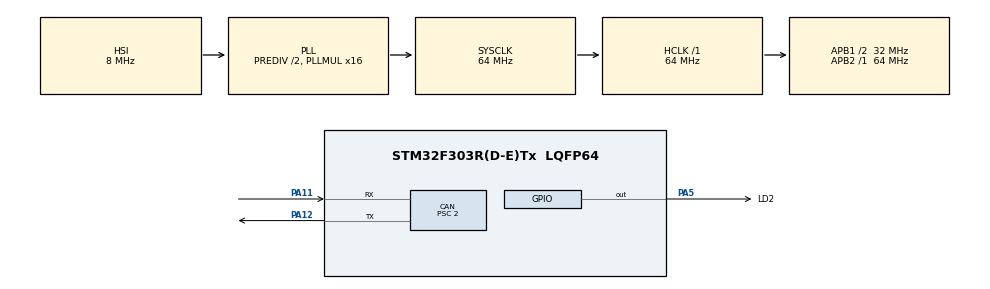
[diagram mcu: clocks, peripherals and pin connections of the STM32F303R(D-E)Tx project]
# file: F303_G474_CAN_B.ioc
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CAN.ABOM=ENABLE
CAN.AWUM=DISABLE
CAN.BS1=CAN_BS1_11TQ
CAN.BS2=CAN_BS2_4TQ
CAN.CalculateBaudRate=1000000
CAN.CalculateTimeBit=1000
CAN.CalculateTimeQuantum=62.5
CAN.Mode=CAN_MODE_NORMAL
CAN.NART=ENABLE
CAN.Prescaler=2
CAN.RFLM=DISABLE
CAN.SJW=CAN_SJW_4TQ
CAN.TTCM=DISABLE
CAN.TXFP=DISABLE
Mcu.Family=STM32F3
Mcu.Name=STM32F303R(D-E)Tx
Mcu.Package=LQFP64
NVIC.PriorityGroup=NVIC_PRIORITYGROUP_4
PA11.Mode=CAN_Activate
PA11.Signal=CAN_RX
PA12.Mode=CAN_Activate
PA12.Signal=CAN_TX
PA13.Signal=SYS_JTMS-SWDIO
PA14.Signal=SYS_JTCK-SWCLK
PA5.GPIO_Label=LD2
PA5.GPIO_Mode=GPIO_MODE_OUTPUT_PP
PA5.GPIO_PuPd=GPIO_NOPULL
PA5.GPIO_Speed=GPIO_SPEED_FREQ_LOW
PA5.Signal=GPIO_Output
ProjectManager.HeapSize=0x200
ProjectManager.StackSize=0x400
ProjectManager.TargetToolchain=STM32CubeIDE
RCC.AHBFreq_Value=64000000
RCC.APB1CLKDivider=RCC_HCLK_DIV2
RCC.APB1Freq_Value=32000000
RCC.APB1TimFreq_Value=64000000
RCC.APB2Freq_Value=64000000
RCC.APB2TimFreq_Value=64000000
RCC.CortexFreq_Value=64000000
RCC.HSE_VALUE=8000000
RCC.HSI_VALUE=8000000
RCC.LSE_VALUE=32768
RCC.PLLMUL=RCC_PLL_MUL16
RCC.PLLSourceVirtual=RCC_PLLSOURCE_HSI
RCC.PREDIV=RCC_PREDIV_DIV2
RCC.SYSCLKFreq_VALUE=64000000
RCC.SYSCLKSource=RCC_SYSCLKSOURCE_PLLCLK
RCC.USBFreq_Value=42666666.666666664
SYS.Debug=Serial Wire
board=custom

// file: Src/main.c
/* USER CODE BEGIN Header */
/**
  ******************************************************************************
  * @file           : main.c
  * @brief          : Main program body
  ******************************************************************************
  * @attention
  *
  * Copyright (c) 2026 STMicroelectronics.
  * All rights reserved.
  *
  * This software is licensed under terms that can be found in the LICENSE file
  * in the root directory of this software component.
  * If no LICENSE file comes with this software, it is provided AS-IS.
  *
  ******************************************************************************
  */
/* USER CODE END Header */
#include "main.h"

/* USER CODE BEGIN Includes */
#include "can_echo_test.h"
/* USER CODE END Includes */

CAN_HandleTypeDef hcan;

void SystemClock_Config(void);
static void MX_GPIO_Init(void);
static void MX_CAN_Init(void);

int main(void)
{

  /* MCU Configuration--------------------------------------------------------*/

  /* Reset of all peripherals, Initializes the Flash interface and the Systick. */
  HAL_Init();

  /* Configure the system clock */
  SystemClock_Config();

  /* Initialize all configured peripherals */
  MX_GPIO_Init();
  MX_CAN_Init();
  /* USER CODE BEGIN 2 */
  CanEcho_Init(&hcan);
  /* USER CODE END 2 */

  /* Infinite loop */
  while (1)
  {

    /* USER CODE BEGIN 3 */
      CanEcho_Poll();
  }
  /* USER CODE END 3 */
}

void SystemClock_Config(void)
{
  RCC_OscInitTypeDef RCC_OscInitStruct = {0};
  RCC_ClkInitTypeDef RCC_ClkInitStruct = {0};

  /** Initializes the RCC Oscillators according to the specified parameters
  * in the RCC_OscInitTypeDef structure.
  */
  RCC_OscInitStruct.OscillatorType = RCC_OSCILLATORTYPE_HSI;
  RCC_OscInitStruct.HSIState = RCC_HSI_ON;
  RCC_OscInitStruct.HSICalibrationValue = RCC_HSICALIBRATION_DEFAULT;
  /* HSI 8 MHz / 2 * 16 = 64 MHz; no external clock dependency. */
  RCC_OscInitStruct.PLL.PLLState = RCC_PLL_ON;
  RCC_OscInitStruct.PLL.PLLSource = RCC_PLLSOURCE_HSI;
  RCC_OscInitStruct.PLL.PREDIV = RCC_PREDIV_DIV2;
  RCC_OscInitStruct.PLL.PLLMUL = RCC_PLL_MUL16;
  if (HAL_RCC_OscConfig(&RCC_OscInitStruct) != HAL_OK)
  {
    Error_Handler();
  }

  /** Initializes the CPU, AHB and APB buses clocks
  */
  RCC_ClkInitStruct.ClockType = RCC_CLOCKTYPE_HCLK|RCC_CLOCKTYPE_SYSCLK
                              |RCC_CLOCKTYPE_PCLK1|RCC_CLOCKTYPE_PCLK2;
  RCC_ClkInitStruct.SYSCLKSource = RCC_SYSCLKSOURCE_PLLCLK;
  RCC_ClkInitStruct.AHBCLKDivider = RCC_SYSCLK_DIV1;
  RCC_ClkInitStruct.APB1CLKDivider = RCC_HCLK_DIV2;
  RCC_ClkInitStruct.APB2CLKDivider = RCC_HCLK_DIV1;

  if (HAL_RCC_ClockConfig(&RCC_ClkInitStruct, FLASH_LATENCY_2) != HAL_OK)
  {
    Error_Handler();
  }
}

static void MX_CAN_Init(void)
{

  hcan.Instance = CAN;
  hcan.Init.Prescaler = 2;
  hcan.Init.Mode = CAN_MODE_NORMAL;
  /* CAN PCLK1 32 MHz / 2 / (1 + 11 + 4) = 1 Mbit/s, 75% sample point. */
  hcan.Init.SyncJumpWidth = CAN_SJW_4TQ;
  hcan.Init.TimeSeg1 = CAN_BS1_11TQ;
  hcan.Init.TimeSeg2 = CAN_BS2_4TQ;
  hcan.Init.TimeTriggeredMode = DISABLE;
  hcan.Init.AutoBusOff = ENABLE;
  hcan.Init.AutoWakeUp = DISABLE;
  hcan.Init.AutoRetransmission = ENABLE;
  hcan.Init.ReceiveFifoLocked = DISABLE;
  hcan.Init.TransmitFifoPriority = DISABLE;
  if (HAL_CAN_Init(&hcan) != HAL_OK)
  {
    Error_Handler();
  }

}

static void MX_GPIO_Init(void)
{
  GPIO_InitTypeDef GPIO_InitStruct = {0};

  /* GPIO Ports Clock Enable */
  __HAL_RCC_GPIOA_CLK_ENABLE();

  /*Configure GPIO pin Output Level */
  HAL_GPIO_WritePin(LD2_GPIO_Port, LD2_Pin, GPIO_PIN_RESET);

  /*Configure GPIO pin : LD2_Pin */
  GPIO_InitStruct.Pin = LD2_Pin;
  GPIO_InitStruct.Mode = GPIO_MODE_OUTPUT_PP;
  GPIO_InitStruct.Pull = GPIO_NOPULL;
  GPIO_InitStruct.Speed = GPIO_SPEED_FREQ_LOW;
  HAL_GPIO_Init(LD2_GPIO_Port, &GPIO_InitStruct);

}

void Error_Handler(void)
{
  __disable_irq();
  while (1)
  {
  }
}
